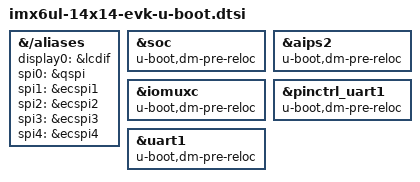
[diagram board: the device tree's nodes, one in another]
// SPDX-License-Identifier: GPL-2.0+
/*
 * Copyright 2018, 2023 NXP
 */

&{/aliases} {
	display0 = &lcdif;

	spi0 = &qspi;
	spi1 = &ecspi1;
	spi2 = &ecspi2;
	spi3 = &ecspi3;
	spi4 = &ecspi4;
};

&soc {
	u-boot,dm-pre-reloc;
	u-boot,dm-spl;
};

&aips2 {
	u-boot,dm-pre-reloc;
	u-boot,dm-spl;
};

&iomuxc {
	u-boot,dm-pre-reloc;
	u-boot,dm-spl;
};

&pinctrl_uart1 {
	u-boot,dm-pre-reloc;
	u-boot,dm-spl;
};

&uart1 {
	u-boot,dm-pre-reloc;
	u-boot,dm-spl;
};
